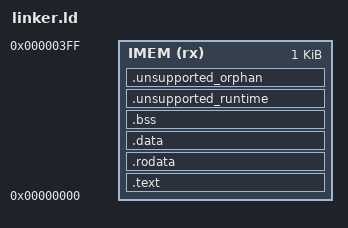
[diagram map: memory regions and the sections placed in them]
OUTPUT_ARCH(riscv)
ENTRY(_start)

MEMORY
{
    IMEM (rx) : ORIGIN = 0x00000000, LENGTH = 1024
}

SECTIONS
{
    .text :
    {
        . = ALIGN(4);
        KEEP(*(.text.startup))
        *(.text)
        *(.text.*)
        . = ALIGN(4);
        __text_end = .;
    } > IMEM

    .rodata :
    {
        *(.rodata)
        *(.rodata.*)
        *(.srodata)
        *(.srodata.*)
    } > IMEM

    .data :
    {
        *(.data)
        *(.data.*)
        *(.sdata)
        *(.sdata.*)
        *(.data.rel.ro)
        *(.data.rel.ro.*)
    } > IMEM

    .bss (NOLOAD) :
    {
        *(.bss)
        *(.bss.*)
        *(.sbss)
        *(.sbss.*)
        *(COMMON)
    } > IMEM

    .unsupported_runtime :
    {
        *(.init)
        *(.init.*)
        *(.fini)
        *(.fini.*)
        *(.preinit_array)
        *(.preinit_array.*)
        *(.init_array)
        *(.init_array.*)
        *(.fini_array)
        *(.fini_array.*)
        *(.ctors)
        *(.ctors.*)
        *(.dtors)
        *(.dtors.*)
        *(.got)
        *(.got.*)
        *(.igot.*)
        *(.plt)
        *(.plt.*)
        *(.iplt)
        *(.iplt.*)
        *(.tdata)
        *(.tdata.*)
        *(.tbss)
        *(.tbss.*)
    } > IMEM

    /DISCARD/ :
    {
        *(.comment)
        *(.eh_frame)
        *(.eh_frame.*)
        *(.note)
        *(.note.*)
        *(.riscv.attributes)
        *(.gnu.attributes)
        *(.debug)
        *(.debug.*)
        *(.zdebug)
        *(.zdebug.*)
        *(.stab)
        *(.stab.*)
        *(.line)
        *(.line.*)
        *(.llvm_addrsig)
    }

    /* Catch every unclassified input section instead of silently letting an
       orphan section escape the IMEM image generated by objcopy. */
    .unsupported_orphan :
    {
        *(*)
    } > IMEM
}

ASSERT(SIZEOF(.data) == 0,
       "Initialized global/static data is not supported by this minimal flow")
ASSERT(SIZEOF(.bss) == 0,
       "Global/static BSS is not supported by this minimal flow")
ASSERT(SIZEOF(.rodata) == 0,
       "Static read-only data is not supported because loads access DMEM, not IMEM")
ASSERT(SIZEOF(.unsupported_runtime) == 0,
       "The program contains an unsupported runtime, GOT, PLT or TLS section")
ASSERT(SIZEOF(.unsupported_orphan) == 0,
       "The program contains an unsupported orphan section")
ASSERT(__text_end <= (ORIGIN(IMEM) + LENGTH(IMEM)),
       "Program does not fit in the 1024-byte instruction memory")
